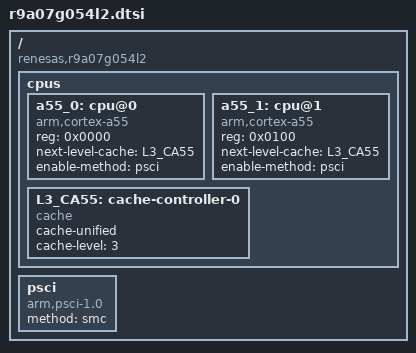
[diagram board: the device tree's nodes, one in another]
// SPDX-License-Identifier: GPL-2.0
/*
 * Device Tree Source for the RZ/V2L Dual A55 (R9A07G054L2) SoC
 *
 * Copyright (C) 2021 Renesas Electronics Corp.
 */

#include "r9a07g044l.dtsi"

/ {
	compatible = "renesas,r9a07g054l2";
	#address-cells = <2>;
	#size-cells = <2>;

	cpus {
		#address-cells = <1>;
		#size-cells = <0>;

		a55_0: cpu@0 {
			compatible = "arm,cortex-a55";
			reg = <0x0000>;
			device_type = "cpu";
			next-level-cache = <&L3_CA55>;
			enable-method = "psci";
		};

		a55_1: cpu@1 {
			compatible = "arm,cortex-a55";
			reg = <0x0100>;
			device_type = "cpu";
			next-level-cache = <&L3_CA55>;
			enable-method = "psci";
		};

		L3_CA55: cache-controller-0 {
			compatible = "cache";
			cache-unified;
			cache-level = <3>;
		};
	};

	psci {
		compatible = "arm,psci-1.0", "arm,psci-0.2";
		method = "smc";
	};
};

